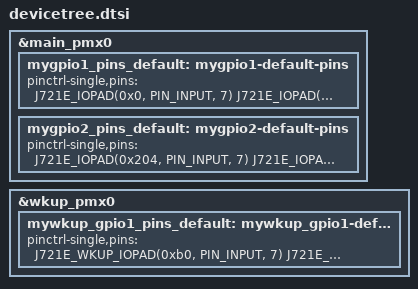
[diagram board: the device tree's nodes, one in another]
/* This file was auto-generated by TI PinMux on 6/28/2024 at 11:03:23 AM. */
/* This file should only be used as a reference. Some pins/peripherals, */
/* depending on your use case, may need additional configuration. */

&main_pmx0 {
	mygpio1_pins_default: mygpio1-default-pins {
		pinctrl-single,pins = <
			J721E_IOPAD(0x0, PIN_INPUT, 7) /* (AC18) EXTINTn.GPIO0_0 */
			J721E_IOPAD(0x4, PIN_INPUT, 7) /* (AC23) PRG1_PRU0_GPO0.GPIO0_1 */
			J721E_IOPAD(0x8, PIN_INPUT, 7) /* (AG22) PRG1_PRU0_GPO1.GPIO0_2 */
			J721E_IOPAD(0xc, PIN_INPUT, 7) /* (AF22) PRG1_PRU0_GPO2.GPIO0_3 */
			J721E_IOPAD(0x10, PIN_INPUT, 7) /* (AJ23) PRG1_PRU0_GPO3.GPIO0_4 */
			J721E_IOPAD(0x14, PIN_INPUT, 7) /* (AH23) PRG1_PRU0_GPO4.GPIO0_5 */
			J721E_IOPAD(0x18, PIN_INPUT, 7) /* (AD20) PRG1_PRU0_GPO5.GPIO0_6 */
			J721E_IOPAD(0x1c, PIN_INPUT, 7) /* (AD22) PRG1_PRU0_GPO6.GPIO0_7 */
			J721E_IOPAD(0x20, PIN_INPUT, 7) /* (AE20) PRG1_PRU0_GPO7.GPIO0_8 */
			J721E_IOPAD(0x24, PIN_INPUT, 7) /* (AJ20) PRG1_PRU0_GPO8.GPIO0_9 */
			J721E_IOPAD(0x28, PIN_INPUT, 7) /* (AG20) PRG1_PRU0_GPO9.GPIO0_10 */
			J721E_IOPAD(0x2c, PIN_INPUT, 7) /* (AD21) PRG1_PRU0_GPO10.GPIO0_11 */
			J721E_IOPAD(0x30, PIN_INPUT, 7) /* (AF24) PRG1_PRU0_GPO11.GPIO0_12 */
			J721E_IOPAD(0x34, PIN_INPUT, 7) /* (AJ24) PRG1_PRU0_GPO12.GPIO0_13 */
			J721E_IOPAD(0x38, PIN_INPUT, 7) /* (AG24) PRG1_PRU0_GPO13.GPIO0_14 */
			J721E_IOPAD(0x3c, PIN_INPUT, 7) /* (AD24) PRG1_PRU0_GPO14.GPIO0_15 */
			J721E_IOPAD(0x40, PIN_INPUT, 7) /* (AC24) PRG1_PRU0_GPO15.GPIO0_16 */
			J721E_IOPAD(0x44, PIN_INPUT, 7) /* (AE24) PRG1_PRU0_GPO16.GPIO0_17 */
			J721E_IOPAD(0x4c, PIN_INPUT, 7) /* (AJ21) PRG1_PRU0_GPO17.GPIO0_18 */
			J721E_IOPAD(0x50, PIN_INPUT, 7) /* (AE21) PRG1_PRU0_GPO18.GPIO0_19 */
			J721E_IOPAD(0x54, PIN_INPUT, 7) /* (AH21) PRG1_PRU0_GPO19.GPIO0_20 */
			J721E_IOPAD(0x58, PIN_INPUT, 7) /* (AE22) PRG1_PRU1_GPO0.GPIO0_21 */
			J721E_IOPAD(0x5c, PIN_INPUT, 7) /* (AG23) PRG1_PRU1_GPO1.GPIO0_22 */
			J721E_IOPAD(0x60, PIN_INPUT, 7) /* (AF23) PRG1_PRU1_GPO2.GPIO0_23 */
			J721E_IOPAD(0x64, PIN_INPUT, 7) /* (AD23) PRG1_PRU1_GPO3.GPIO0_24 */
			J721E_IOPAD(0x68, PIN_INPUT, 7) /* (AH24) PRG1_PRU1_GPO4.GPIO0_25 */
			J721E_IOPAD(0x6c, PIN_INPUT, 7) /* (AG21) PRG1_PRU1_GPO5.GPIO0_26 */
			J721E_IOPAD(0x70, PIN_INPUT, 7) /* (AE23) PRG1_PRU1_GPO6.GPIO0_27 */
			J721E_IOPAD(0x74, PIN_INPUT, 7) /* (AC21) PRG1_PRU1_GPO7.GPIO0_28 */
			J721E_IOPAD(0x78, PIN_INPUT, 7) /* (Y23) PRG1_PRU1_GPO8.GPIO0_29 */
			J721E_IOPAD(0x7c, PIN_INPUT, 7) /* (AF21) PRG1_PRU1_GPO9.GPIO0_30 */
			J721E_IOPAD(0x80, PIN_INPUT, 7) /* (AB23) PRG1_PRU1_GPO10.GPIO0_31 */
			J721E_IOPAD(0x84, PIN_INPUT, 7) /* (AJ25) PRG1_PRU1_GPO11.GPIO0_32 */
			J721E_IOPAD(0x88, PIN_INPUT, 7) /* (AH25) PRG1_PRU1_GPO12.GPIO0_33 */
			J721E_IOPAD(0x8c, PIN_INPUT, 7) /* (AG25) PRG1_PRU1_GPO13.GPIO0_34 */
			J721E_IOPAD(0x90, PIN_INPUT, 7) /* (AH26) PRG1_PRU1_GPO14.GPIO0_35 */
			J721E_IOPAD(0x94, PIN_INPUT, 7) /* (AJ27) PRG1_PRU1_GPO15.GPIO0_36 */
			J721E_IOPAD(0x98, PIN_INPUT, 7) /* (AJ26) PRG1_PRU1_GPO16.GPIO0_37 */
			J721E_IOPAD(0x9c, PIN_INPUT, 7) /* (AC22) PRG1_PRU1_GPO17.GPIO0_38 */
			J721E_IOPAD(0xa0, PIN_INPUT, 7) /* (AJ22) PRG1_PRU1_GPO18.GPIO0_39 */
			J721E_IOPAD(0xa4, PIN_INPUT, 7) /* (AH22) PRG1_PRU1_GPO19.GPIO0_40 */
			J721E_IOPAD(0xa8, PIN_INPUT, 7) /* (AD19) PRG1_MDIO0_MDIO.GPIO0_41 */
			J721E_IOPAD(0xac, PIN_INPUT, 7) /* (AD18) PRG1_MDIO0_MDC.GPIO0_42 */
			J721E_IOPAD(0xb0, PIN_INPUT, 7) /* (AF28) PRG0_PRU0_GPO0.GPIO0_43 */
			J721E_IOPAD(0xb4, PIN_INPUT, 7) /* (AE28) PRG0_PRU0_GPO1.GPIO0_44 */
			J721E_IOPAD(0xb8, PIN_INPUT, 7) /* (AE27) PRG0_PRU0_GPO2.GPIO0_45 */
			J721E_IOPAD(0xbc, PIN_INPUT, 7) /* (AD26) PRG0_PRU0_GPO3.GPIO0_46 */
			J721E_IOPAD(0xc0, PIN_INPUT, 7) /* (AD25) PRG0_PRU0_GPO4.GPIO0_47 */
			J721E_IOPAD(0xc4, PIN_INPUT, 7) /* (AC29) PRG0_PRU0_GPO5.GPIO0_48 */
			J721E_IOPAD(0xc8, PIN_INPUT, 7) /* (AE26) PRG0_PRU0_GPO6.GPIO0_49 */
			J721E_IOPAD(0xcc, PIN_INPUT, 7) /* (AC28) PRG0_PRU0_GPO7.GPIO0_50 */
			J721E_IOPAD(0xd0, PIN_INPUT, 7) /* (AC27) PRG0_PRU0_GPO8.GPIO0_51 */
			J721E_IOPAD(0xd4, PIN_INPUT, 7) /* (AB26) PRG0_PRU0_GPO9.GPIO0_52 */
			J721E_IOPAD(0xd8, PIN_INPUT, 7) /* (AB25) PRG0_PRU0_GPO10.GPIO0_53 */
			J721E_IOPAD(0xdc, PIN_INPUT, 7) /* (AJ28) PRG0_PRU0_GPO11.GPIO0_54 */
			J721E_IOPAD(0xe0, PIN_INPUT, 7) /* (AH27) PRG0_PRU0_GPO12.GPIO0_55 */
			J721E_IOPAD(0xe4, PIN_INPUT, 7) /* (AH29) PRG0_PRU0_GPO13.GPIO0_56 */
			J721E_IOPAD(0xe8, PIN_INPUT, 7) /* (AG28) PRG0_PRU0_GPO14.GPIO0_57 */
			J721E_IOPAD(0xec, PIN_INPUT, 7) /* (AG27) PRG0_PRU0_GPO15.GPIO0_58 */
			J721E_IOPAD(0xf0, PIN_INPUT, 7) /* (AH28) PRG0_PRU0_GPO16.GPIO0_59 */
			J721E_IOPAD(0xf4, PIN_INPUT, 7) /* (AB24) PRG0_PRU0_GPO17.GPIO0_60 */
			J721E_IOPAD(0xf8, PIN_INPUT, 7) /* (AB29) PRG0_PRU0_GPO18.GPIO0_61 */
			J721E_IOPAD(0xfc, PIN_INPUT, 7) /* (AB28) PRG0_PRU0_GPO19.GPIO0_62 */
			J721E_IOPAD(0x100, PIN_INPUT, 7) /* (AE29) PRG0_PRU1_GPO0.GPIO0_63 */
			J721E_IOPAD(0x104, PIN_INPUT, 7) /* (AD28) PRG0_PRU1_GPO1.GPIO0_64 */
			J721E_IOPAD(0x108, PIN_INPUT, 7) /* (AD27) PRG0_PRU1_GPO2.GPIO0_65 */
			J721E_IOPAD(0x10c, PIN_INPUT, 7) /* (AC25) PRG0_PRU1_GPO3.GPIO0_66 */
			J721E_IOPAD(0x110, PIN_INPUT, 7) /* (AD29) PRG0_PRU1_GPO4.GPIO0_67 */
			J721E_IOPAD(0x114, PIN_INPUT, 7) /* (AB27) PRG0_PRU1_GPO5.GPIO0_68 */
			J721E_IOPAD(0x118, PIN_INPUT, 7) /* (AC26) PRG0_PRU1_GPO6.GPIO0_69 */
			J721E_IOPAD(0x11c, PIN_INPUT, 7) /* (AA24) PRG0_PRU1_GPO7.GPIO0_70 */
			J721E_IOPAD(0x120, PIN_INPUT, 7) /* (AA28) PRG0_PRU1_GPO8.GPIO0_71 */
			J721E_IOPAD(0x124, PIN_INPUT, 7) /* (Y24) PRG0_PRU1_GPO9.GPIO0_72 */
			J721E_IOPAD(0x128, PIN_INPUT, 7) /* (AA25) PRG0_PRU1_GPO10.GPIO0_73 */
			J721E_IOPAD(0x12c, PIN_INPUT, 7) /* (AG26) PRG0_PRU1_GPO11.GPIO0_74 */
			J721E_IOPAD(0x130, PIN_INPUT, 7) /* (AF27) PRG0_PRU1_GPO12.GPIO0_75 */
			J721E_IOPAD(0x134, PIN_INPUT, 7) /* (AF26) PRG0_PRU1_GPO13.GPIO0_76 */
			J721E_IOPAD(0x138, PIN_INPUT, 7) /* (AE25) PRG0_PRU1_GPO14.GPIO0_77 */
			J721E_IOPAD(0x13c, PIN_INPUT, 7) /* (AF29) PRG0_PRU1_GPO15.GPIO0_78 */
			J721E_IOPAD(0x140, PIN_INPUT, 7) /* (AG29) PRG0_PRU1_GPO16.GPIO0_79 */
			J721E_IOPAD(0x144, PIN_INPUT, 7) /* (Y25) PRG0_PRU1_GPO17.GPIO0_80 */
			J721E_IOPAD(0x148, PIN_INPUT, 7) /* (AA26) PRG0_PRU1_GPO18.GPIO0_81 */
			J721E_IOPAD(0x14c, PIN_INPUT, 7) /* (AA29) PRG0_PRU1_GPO19.GPIO0_82 */
			J721E_IOPAD(0x150, PIN_INPUT, 7) /* (Y26) PRG0_MDIO0_MDIO.GPIO0_83 */
			J721E_IOPAD(0x154, PIN_INPUT, 7) /* (AA27) PRG0_MDIO0_MDC.GPIO0_84 */
			J721E_IOPAD(0x158, PIN_INPUT, 7) /* (U23) RGMII5_TX_CTL.GPIO0_85 */
			J721E_IOPAD(0x15c, PIN_INPUT, 7) /* (U26) RGMII5_RX_CTL.GPIO0_86 */
			J721E_IOPAD(0x160, PIN_INPUT, 7) /* (V28) RGMII5_TD3.GPIO0_87 */
			J721E_IOPAD(0x164, PIN_INPUT, 7) /* (V29) RGMII5_TD2.GPIO0_88 */
			J721E_IOPAD(0x168, PIN_INPUT, 7) /* (V27) RGMII5_TD1.GPIO0_89 */
			J721E_IOPAD(0x16c, PIN_INPUT, 7) /* (U28) RGMII5_TD0.GPIO0_90 */
			J721E_IOPAD(0x170, PIN_INPUT, 7) /* (U29) RGMII5_TXC.GPIO0_91 */
			J721E_IOPAD(0x174, PIN_INPUT, 7) /* (U25) RGMII5_RXC.GPIO0_92 */
			J721E_IOPAD(0x178, PIN_INPUT, 7) /* (U27) RGMII5_RD3.GPIO0_93 */
			J721E_IOPAD(0x17c, PIN_INPUT, 7) /* (U24) RGMII5_RD2.GPIO0_94 */
			J721E_IOPAD(0x180, PIN_INPUT, 7) /* (R23) RGMII5_RD1.GPIO0_95 */
			J721E_IOPAD(0x184, PIN_INPUT, 7) /* (T23) RGMII5_RD0.GPIO0_96 */
			J721E_IOPAD(0x188, PIN_INPUT, 7) /* (Y28) RGMII6_TX_CTL.GPIO0_97 */
			J721E_IOPAD(0x18c, PIN_INPUT, 7) /* (V23) RGMII6_RX_CTL.GPIO0_98 */
			J721E_IOPAD(0x190, PIN_INPUT, 7) /* (W23) RGMII6_TD3.GPIO0_99 */
			J721E_IOPAD(0x194, PIN_INPUT, 7) /* (W28) RGMII6_TD2.GPIO0_100 */
			J721E_IOPAD(0x198, PIN_INPUT, 7) /* (V25) RGMII6_TD1.GPIO0_101 */
			J721E_IOPAD(0x19c, PIN_INPUT, 7) /* (W27) RGMII6_TD0.GPIO0_102 */
			J721E_IOPAD(0x1a0, PIN_INPUT, 7) /* (W29) RGMII6_TXC.GPIO0_103 */
			J721E_IOPAD(0x1a4, PIN_INPUT, 7) /* (W26) RGMII6_RXC.GPIO0_104 */
			J721E_IOPAD(0x1a8, PIN_INPUT, 7) /* (Y29) RGMII6_RD3.GPIO0_105 */
			J721E_IOPAD(0x1ac, PIN_INPUT, 7) /* (Y27) RGMII6_RD2.GPIO0_106 */
			J721E_IOPAD(0x1b0, PIN_INPUT, 7) /* (W24) RGMII6_RD1.GPIO0_107 */
			J721E_IOPAD(0x1b4, PIN_INPUT, 7) /* (W25) RGMII6_RD0.GPIO0_108 */
			J721E_IOPAD(0x1b8, PIN_INPUT, 7) /* (V26) MDIO0_MDIO.GPIO0_109 */
			J721E_IOPAD(0x1bc, PIN_INPUT, 7) /* (V24) MDIO0_MDC.GPIO0_110 */
			J721E_IOPAD(0x1c0, PIN_INPUT, 7) /* (AA2) SPI0_CS0.GPIO0_111 */
			J721E_IOPAD(0x1c4, PIN_INPUT, 7) /* (Y4) SPI0_CS1.GPIO0_112 */
			J721E_IOPAD(0x1c8, PIN_INPUT, 7) /* (AA1) SPI0_CLK.GPIO0_113 */
			J721E_IOPAD(0x1cc, PIN_INPUT, 7) /* (AB5) SPI0_D0.GPIO0_114 */
			J721E_IOPAD(0x1d0, PIN_INPUT, 7) /* (AA3) SPI0_D1.GPIO0_115 */
			J721E_IOPAD(0x1d4, PIN_INPUT, 7) /* (Y3) SPI1_CS0.GPIO0_116 */
			J721E_IOPAD(0x1d8, PIN_INPUT, 7) /* (W4) SPI1_CS1.GPIO0_117 */
			J721E_IOPAD(0x1dc, PIN_INPUT, 7) /* (Y1) SPI1_CLK.GPIO0_118 */
			J721E_IOPAD(0x1e0, PIN_INPUT, 7) /* (Y5) SPI1_D0.GPIO0_119 */
			J721E_IOPAD(0x1e4, PIN_INPUT, 7) /* (Y2) SPI1_D1.GPIO0_120 */
			J721E_IOPAD(0x1e8, PIN_INPUT, 7) /* (AB2) UART0_RXD.GPIO0_121 */
			J721E_IOPAD(0x1ec, PIN_INPUT, 7) /* (AB3) UART0_TXD.GPIO0_122 */
			J721E_IOPAD(0x1f0, PIN_INPUT, 7) /* (AC2) UART0_CTSn.GPIO0_123 */
			J721E_IOPAD(0x1f4, PIN_INPUT, 7) /* (AB1) UART0_RTSn.GPIO0_124 */
			J721E_IOPAD(0x1f8, PIN_INPUT, 7) /* (AA4) UART1_RXD.GPIO0_125 */
			J721E_IOPAD(0x1fc, PIN_INPUT, 7) /* (AB4) UART1_TXD.GPIO0_126 */
			J721E_IOPAD(0x200, PIN_INPUT, 7) /* (AC4) UART1_CTSn.GPIO0_127 */
		>;
	};

	mygpio2_pins_default: mygpio2-default-pins {
		pinctrl-single,pins = <
			J721E_IOPAD(0x204, PIN_INPUT, 7) /* (AD5) UART1_RTSn.GPIO1_0 */
			J721E_IOPAD(0x208, PIN_INPUT, 7) /* (W5) MCAN0_RX.GPIO1_1 */
			J721E_IOPAD(0x20c, PIN_INPUT, 7) /* (W6) MCAN0_TX.GPIO1_2 */
			J721E_IOPAD(0x210, PIN_INPUT, 7) /* (W3) MCAN1_RX.GPIO1_3 */
			J721E_IOPAD(0x214, PIN_INPUT, 7) /* (V4) MCAN1_TX.GPIO1_4 */
			J721E_IOPAD(0x218, PIN_INPUT, 7) /* (W2) I3C0_SCL.GPIO1_5 */
			J721E_IOPAD(0x21c, PIN_INPUT, 7) /* (W1) I3C0_SDA.GPIO1_6 */
			J721E_IOPAD(0x220, PIN_INPUT, 7) /* (AC5) I2C0_SCL.GPIO1_7 */
			J721E_IOPAD(0x224, PIN_INPUT, 7) /* (AA5) I2C0_SDA.GPIO1_8 */
			J721E_IOPAD(0x228, PIN_INPUT, 7) /* (Y6) I2C1_SCL.GPIO1_9 */
			J721E_IOPAD(0x22c, PIN_INPUT, 7) /* (AA6) I2C1_SDA.GPIO1_10 */
			J721E_IOPAD(0x230, PIN_INPUT, 7) /* (U2) ECAP0_IN_APWM_OUT.GPIO1_11 */
			J721E_IOPAD(0x234, PIN_INPUT, 7) /* (U3) EXT_REFCLK1.GPIO1_12 */
			J721E_IOPAD(0x238, PIN_INPUT, 7) /* (V6) TIMER_IO0.GPIO1_13 */
			J721E_IOPAD(0x23c, PIN_INPUT, 7) /* (V5) TIMER_IO1.GPIO1_14 */
			J721E_IOPAD(0x240, PIN_INPUT, 7) /* (R26) MMC1_DAT3.GPIO1_15 */
			J721E_IOPAD(0x244, PIN_INPUT, 7) /* (R25) MMC1_DAT2.GPIO1_16 */
			J721E_IOPAD(0x248, PIN_INPUT, 7) /* (P24) MMC1_DAT1.GPIO1_17 */
			J721E_IOPAD(0x24c, PIN_INPUT, 7) /* (R24) MMC1_DAT0.GPIO1_18 */
			J721E_IOPAD(0x250, PIN_INPUT, 7) /* (P25) MMC1_CLK.GPIO1_19 */
			J721E_IOPAD(0x254, PIN_INPUT, 7) /* (R29) MMC1_CMD.GPIO1_20 */
			J721E_IOPAD(0x258, PIN_INPUT, 7) /* (P23) MMC1_SDCD.GPIO1_21 */
			J721E_IOPAD(0x25c, PIN_INPUT, 7) /* (R28) MMC1_SDWP.GPIO1_22 */
			J721E_IOPAD(0x260, PIN_INPUT, 7) /* (T28) MMC2_DAT3.GPIO1_23 */
			J721E_IOPAD(0x264, PIN_INPUT, 7) /* (T29) MMC2_DAT2.GPIO1_24 */
			J721E_IOPAD(0x268, PIN_INPUT, 7) /* (T27) MMC2_DAT1.GPIO1_25 */
			J721E_IOPAD(0x26c, PIN_INPUT, 7) /* (T24) MMC2_DAT0.GPIO1_26 */
			J721E_IOPAD(0x270, PIN_INPUT, 7) /* (T26) MMC2_CLK.GPIO1_27 */
			J721E_IOPAD(0x274, PIN_INPUT, 7) /* (T25) MMC2_CMD.GPIO1_28 */
			J721E_IOPAD(0x290, PIN_INPUT, 7) /* (U6) USB0_DRVVBUS.GPIO1_29 */
			J721E_IOPAD(0x294, PIN_INPUT, 7) /* (AD1) MLB0_MLBSP.GPIO1_30 */
			J721E_IOPAD(0x298, PIN_INPUT, 7) /* (AC1) MLB0_MLBSN.GPIO1_31 */
			J721E_IOPAD(0x29c, PIN_INPUT, 7) /* (AC3) MLB0_MLBDP.GPIO1_32 */
			J721E_IOPAD(0x2a0, PIN_INPUT, 7) /* (AD3) MLB0_MLBDN.GPIO1_33 */
			J721E_IOPAD(0x2a4, PIN_INPUT, 7) /* (AD2) MLB0_MLBCP.GPIO1_34 */
			J721E_IOPAD(0x2a8, PIN_INPUT, 7) /* (AE2) MLB0_MLBCN.GPIO1_35 */
		>;
	};

};

&wkup_pmx0 {
	mywkup_gpio1_pins_default: mywkup_gpio1-default-pins {
		pinctrl-single,pins = <
			J721E_WKUP_IOPAD(0xb0, PIN_INPUT, 7) /* (F26) WKUP_GPIO0_0 */
			J721E_WKUP_IOPAD(0xb4, PIN_INPUT, 7) /* (F25) WKUP_GPIO0_1 */
			J721E_WKUP_IOPAD(0xb8, PIN_INPUT, 7) /* (F28) WKUP_GPIO0_2 */
			J721E_WKUP_IOPAD(0xbc, PIN_INPUT, 7) /* (F27) WKUP_GPIO0_3 */
			J721E_WKUP_IOPAD(0xc0, PIN_INPUT, 7) /* (G25) WKUP_GPIO0_4 */
			J721E_WKUP_IOPAD(0xc4, PIN_INPUT, 7) /* (G24) WKUP_GPIO0_5 */
			J721E_WKUP_IOPAD(0xc8, PIN_INPUT, 7) /* (F29) WKUP_GPIO0_6 */
			J721E_WKUP_IOPAD(0xcc, PIN_INPUT, 7) /* (G28) WKUP_GPIO0_7 */
			J721E_WKUP_IOPAD(0xd0, PIN_INPUT, 7) /* (G27) WKUP_GPIO0_8 */
			J721E_WKUP_IOPAD(0xd4, PIN_INPUT, 7) /* (G26) WKUP_GPIO0_9 */
			J721E_WKUP_IOPAD(0xd8, PIN_INPUT, 7) /* (H26) WKUP_GPIO0_10 */
			J721E_WKUP_IOPAD(0xdc, PIN_INPUT, 7) /* (H27) WKUP_GPIO0_11 */
			J721E_WKUP_IOPAD(0xe0, PIN_INPUT, 7) /* (G29) WKUP_GPIO0_12 */
			J721E_WKUP_IOPAD(0xe4, PIN_INPUT, 7) /* (H28) WKUP_GPIO0_13 */
			J721E_WKUP_IOPAD(0xe8, PIN_INPUT, 7) /* (H29) WKUP_GPIO0_14 */
			J721E_WKUP_IOPAD(0xec, PIN_INPUT, 7) /* (J27) WKUP_GPIO0_15 */
			J721E_WKUP_IOPAD(0x0, PIN_INPUT, 7) /* (E20) MCU_OSPI0_CLK.WKUP_GPIO0_16 */
			J721E_WKUP_IOPAD(0x4, PIN_INPUT, 7) /* (C21) MCU_OSPI0_LBCLKO.WKUP_GPIO0_17 */
			J721E_WKUP_IOPAD(0x8, PIN_INPUT, 7) /* (D21) MCU_OSPI0_DQS.WKUP_GPIO0_18 */
			J721E_WKUP_IOPAD(0xc, PIN_INPUT, 7) /* (D20) MCU_OSPI0_D0.WKUP_GPIO0_19 */
			J721E_WKUP_IOPAD(0x10, PIN_INPUT, 7) /* (G19) MCU_OSPI0_D1.WKUP_GPIO0_20 */
			J721E_WKUP_IOPAD(0x14, PIN_INPUT, 7) /* (G20) MCU_OSPI0_D2.WKUP_GPIO0_21 */
			J721E_WKUP_IOPAD(0x18, PIN_INPUT, 7) /* (F20) MCU_OSPI0_D3.WKUP_GPIO0_22 */
			J721E_WKUP_IOPAD(0x1c, PIN_INPUT, 7) /* (F21) MCU_OSPI0_D4.WKUP_GPIO0_23 */
			J721E_WKUP_IOPAD(0x20, PIN_INPUT, 7) /* (E21) MCU_OSPI0_D5.WKUP_GPIO0_24 */
			J721E_WKUP_IOPAD(0x24, PIN_INPUT, 7) /* (B22) MCU_OSPI0_D6.WKUP_GPIO0_25 */
			J721E_WKUP_IOPAD(0x28, PIN_INPUT, 7) /* (G21) MCU_OSPI0_D7.WKUP_GPIO0_26 */
			J721E_WKUP_IOPAD(0x2c, PIN_INPUT, 7) /* (F19) MCU_OSPI0_CSn0.WKUP_GPIO0_27 */
			J721E_WKUP_IOPAD(0x30, PIN_INPUT, 7) /* (E19) MCU_OSPI0_CSn1.WKUP_GPIO0_28 */
			J721E_WKUP_IOPAD(0x34, PIN_INPUT, 7) /* (F22) MCU_OSPI1_CLK.WKUP_GPIO0_29 */
			J721E_WKUP_IOPAD(0x38, PIN_INPUT, 7) /* (A23) MCU_OSPI1_LBCLKO.WKUP_GPIO0_30 */
			J721E_WKUP_IOPAD(0x3c, PIN_INPUT, 7) /* (B23) MCU_OSPI1_DQS.WKUP_GPIO0_31 */
			J721E_WKUP_IOPAD(0x40, PIN_INPUT, 7) /* (D22) MCU_OSPI1_D0.WKUP_GPIO0_32 */
			J721E_WKUP_IOPAD(0x44, PIN_INPUT, 7) /* (G22) MCU_OSPI1_D1.WKUP_GPIO0_33 */
			J721E_WKUP_IOPAD(0x48, PIN_INPUT, 7) /* (D23) MCU_OSPI1_D2.WKUP_GPIO0_34 */
			J721E_WKUP_IOPAD(0x4c, PIN_INPUT, 7) /* (C23) MCU_OSPI1_D3.WKUP_GPIO0_35 */
			J721E_WKUP_IOPAD(0x50, PIN_INPUT, 7) /* (C22) MCU_OSPI1_CSn0.WKUP_GPIO0_36 */
			J721E_WKUP_IOPAD(0x54, PIN_INPUT, 7) /* (E22) MCU_OSPI1_CSn1.WKUP_GPIO0_37 */
			J721E_WKUP_IOPAD(0x58, PIN_INPUT, 7) /* (B27) MCU_RGMII1_TX_CTL.WKUP_GPIO0_38 */
			J721E_WKUP_IOPAD(0x5c, PIN_INPUT, 7) /* (C25) MCU_RGMII1_RX_CTL.WKUP_GPIO0_39 */
			J721E_WKUP_IOPAD(0x60, PIN_INPUT, 7) /* (A28) MCU_RGMII1_TD3.WKUP_GPIO0_40 */
			J721E_WKUP_IOPAD(0x64, PIN_INPUT, 7) /* (A27) MCU_RGMII1_TD2.WKUP_GPIO0_41 */
			J721E_WKUP_IOPAD(0x68, PIN_INPUT, 7) /* (A26) MCU_RGMII1_TD1.WKUP_GPIO0_42 */
			J721E_WKUP_IOPAD(0x6c, PIN_INPUT, 7) /* (B25) MCU_RGMII1_TD0.WKUP_GPIO0_43 */
			J721E_WKUP_IOPAD(0x70, PIN_INPUT, 7) /* (B26) MCU_RGMII1_TXC.WKUP_GPIO0_44 */
			J721E_WKUP_IOPAD(0x74, PIN_INPUT, 7) /* (C24) MCU_RGMII1_RXC.WKUP_GPIO0_45 */
			J721E_WKUP_IOPAD(0x78, PIN_INPUT, 7) /* (A25) MCU_RGMII1_RD3.WKUP_GPIO0_46 */
			J721E_WKUP_IOPAD(0x7c, PIN_INPUT, 7) /* (D24) MCU_RGMII1_RD2.WKUP_GPIO0_47 */
			J721E_WKUP_IOPAD(0x80, PIN_INPUT, 7) /* (A24) MCU_RGMII1_RD1.WKUP_GPIO0_48 */
			J721E_WKUP_IOPAD(0x84, PIN_INPUT, 7) /* (B24) MCU_RGMII1_RD0.WKUP_GPIO0_49 */
			J721E_WKUP_IOPAD(0x88, PIN_INPUT, 7) /* (E23) MCU_MDIO0_MDIO.WKUP_GPIO0_50 */
			J721E_WKUP_IOPAD(0x8c, PIN_INPUT, 7) /* (F23) MCU_MDIO0_MDC.WKUP_GPIO0_51 */
			J721E_WKUP_IOPAD(0x90, PIN_INPUT, 7) /* (E27) MCU_SPI0_CLK.WKUP_GPIO0_52 */
			J721E_WKUP_IOPAD(0x94, PIN_INPUT, 7) /* (E24) MCU_SPI0_D0.WKUP_GPIO0_53 */
			J721E_WKUP_IOPAD(0x98, PIN_INPUT, 7) /* (E28) MCU_SPI0_D1.WKUP_GPIO0_54 */
			J721E_WKUP_IOPAD(0x9c, PIN_INPUT, 7) /* (E25) MCU_SPI0_CS0.WKUP_GPIO0_55 */
			J721E_WKUP_IOPAD(0xa0, PIN_INPUT, 7) /* (J29) WKUP_UART0_RXD.WKUP_GPIO0_56 */
			J721E_WKUP_IOPAD(0xa4, PIN_INPUT, 7) /* (J28) WKUP_UART0_TXD.WKUP_GPIO0_57 */
			J721E_WKUP_IOPAD(0xa8, PIN_INPUT, 7) /* (D29) MCU_MCAN0_TX.WKUP_GPIO0_58 */
			J721E_WKUP_IOPAD(0xac, PIN_INPUT, 7) /* (C29) MCU_MCAN0_RX.WKUP_GPIO0_59 */
			J721E_WKUP_IOPAD(0xf0, PIN_INPUT, 7) /* (D26) MCU_I3C0_SCL.WKUP_GPIO0_60 */
			J721E_WKUP_IOPAD(0xf4, PIN_INPUT, 7) /* (D25) MCU_I3C0_SDA.WKUP_GPIO0_61 */
			J721E_WKUP_IOPAD(0xf8, PIN_INPUT, 7) /* (J25) WKUP_I2C0_SCL.WKUP_GPIO0_62 */
			J721E_WKUP_IOPAD(0xfc, PIN_INPUT, 7) /* (H24) WKUP_I2C0_SDA.WKUP_GPIO0_63 */
			J721E_WKUP_IOPAD(0x100, PIN_INPUT, 7) /* (J26) MCU_I2C0_SCL.WKUP_GPIO0_64 */
			J721E_WKUP_IOPAD(0x104, PIN_INPUT, 7) /* (H25) MCU_I2C0_SDA.WKUP_GPIO0_65 */
			J721E_WKUP_IOPAD(0x108, PIN_INPUT, 7) /* (E26) PMIC_POWER_EN0.WKUP_GPIO0_66 */
			J721E_WKUP_IOPAD(0x10c, PIN_INPUT, 7) /* (G23) PMIC_POWER_EN1.WKUP_GPIO0_67 */
		>;
	};

};
